VERSION ""

NS_ :

BS_:

BU_: RS02

# RS02 telemetry split across two 8-byte frames (Classical CAN)
# Frame IDs chosen as examples; adjust to real IDs when available.

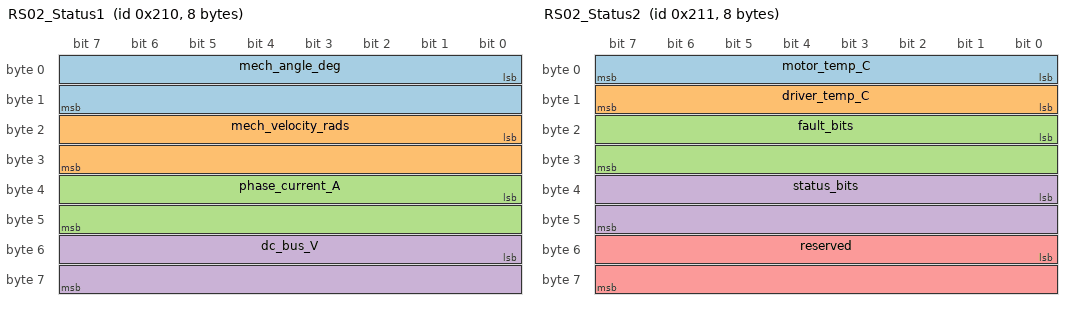
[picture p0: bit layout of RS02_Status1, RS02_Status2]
BO_ 528 RS02_Status1: 8 RS02
 SG_ mech_angle_deg     : 0|16@1+ (0.1,0) [0|3600] "deg" RS02
 SG_ mech_velocity_rads : 16|16@1+ (0.01,0) [-1000|1000] "rad/s" RS02
 SG_ phase_current_A    : 32|16@1+ (0.01,0) [0|500] "A" RS02
 SG_ dc_bus_V           : 48|16@1+ (0.01,0) [0|1000] "V" RS02

BO_ 529 RS02_Status2: 8 RS02
 SG_ motor_temp_C   : 0|8@1+ (1,0) [-40|200] "C" RS02
 SG_ driver_temp_C  : 8|8@1+ (1,0) [-40|200] "C" RS02
 SG_ fault_bits     : 16|16@1+ (1,0) [0|65535] "" RS02
 SG_ status_bits    : 32|16@1+ (1,0) [0|65535] "" RS02
 SG_ reserved       : 48|16@1+ (1,0) [0|65535] "" RS02
